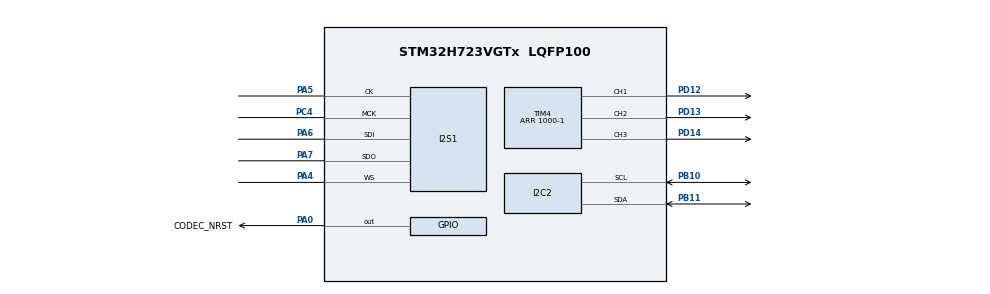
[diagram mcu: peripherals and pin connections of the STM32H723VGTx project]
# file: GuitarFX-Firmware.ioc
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CORTEX_M7.default_mode_Activation=1
Dma.Request0=SPI1_TX
Dma.Request1=SPI1_RX
Dma.SPI1_RX.1.Direction=DMA_PERIPH_TO_MEMORY
Dma.SPI1_RX.1.EventEnable=DISABLE
Dma.SPI1_RX.1.FIFOMode=DMA_FIFOMODE_DISABLE
Dma.SPI1_RX.1.Instance=DMA1_Stream1
Dma.SPI1_RX.1.MemDataAlignment=DMA_MDATAALIGN_WORD
Dma.SPI1_RX.1.MemInc=DMA_MINC_ENABLE
Dma.SPI1_RX.1.Mode=DMA_CIRCULAR
Dma.SPI1_RX.1.PeriphDataAlignment=DMA_PDATAALIGN_WORD
Dma.SPI1_RX.1.PeriphInc=DMA_PINC_DISABLE
Dma.SPI1_RX.1.Polarity=HAL_DMAMUX_REQ_GEN_RISING
Dma.SPI1_RX.1.Priority=DMA_PRIORITY_VERY_HIGH
Dma.SPI1_RX.1.RequestNumber=1
Dma.SPI1_RX.1.SignalID=NONE
Dma.SPI1_RX.1.SyncEnable=DISABLE
Dma.SPI1_RX.1.SyncPolarity=HAL_DMAMUX_SYNC_NO_EVENT
Dma.SPI1_RX.1.SyncRequestNumber=1
Dma.SPI1_RX.1.SyncSignalID=NONE
Dma.SPI1_TX.0.Direction=DMA_MEMORY_TO_PERIPH
Dma.SPI1_TX.0.EventEnable=DISABLE
Dma.SPI1_TX.0.FIFOMode=DMA_FIFOMODE_DISABLE
Dma.SPI1_TX.0.Instance=DMA1_Stream0
Dma.SPI1_TX.0.MemDataAlignment=DMA_MDATAALIGN_WORD
Dma.SPI1_TX.0.MemInc=DMA_MINC_ENABLE
Dma.SPI1_TX.0.Mode=DMA_CIRCULAR
Dma.SPI1_TX.0.PeriphDataAlignment=DMA_PDATAALIGN_WORD
Dma.SPI1_TX.0.PeriphInc=DMA_PINC_DISABLE
Dma.SPI1_TX.0.Polarity=HAL_DMAMUX_REQ_GEN_RISING
Dma.SPI1_TX.0.Priority=DMA_PRIORITY_VERY_HIGH
Dma.SPI1_TX.0.RequestNumber=1
Dma.SPI1_TX.0.SignalID=NONE
Dma.SPI1_TX.0.SyncEnable=DISABLE
Dma.SPI1_TX.0.SyncPolarity=HAL_DMAMUX_SYNC_NO_EVENT
Dma.SPI1_TX.0.SyncRequestNumber=1
Dma.SPI1_TX.0.SyncSignalID=NONE
I2C2.Timing=0x60404E72
I2S1.AudioFreq=I2S_AUDIOFREQ_32K
I2S1.Data24BitAlignment=I2S_DATA_24BIT_ALIGNMENT_LEFT
I2S1.DataFormat=I2S_DATAFORMAT_24B
I2S1.ErrorAudioFreq=1.72 %
I2S1.Instance=SPI$Index
I2S1.RealAudioFreq=32.552 KHz
Mcu.Family=STM32H7
Mcu.Name=STM32H723VGTx
Mcu.Package=LQFP100
NVIC.DMA1_Stream0_IRQn=true\:0\:0\:false\:false\:true\:false\:true\:true
NVIC.DMA1_Stream1_IRQn=true\:0\:0\:false\:false\:true\:false\:true\:true
NVIC.PriorityGroup=NVIC_PRIORITYGROUP_4
PA0.GPIO_Label=CODEC_NRST
PA0.Signal=GPIO_Output
PA13(JTMS/SWDIO).Mode=Trace_Asynchronous_SW
PA13(JTMS/SWDIO).Signal=DEBUG_JTMS-SWDIO
PA14(JTCK/SWCLK).Mode=Trace_Asynchronous_SW
PA14(JTCK/SWCLK).Signal=DEBUG_JTCK-SWCLK
PA4.Mode=Full_Duplex_Master
PA4.Signal=I2S1_WS
PA5.Mode=Full_Duplex_Master
PA5.Signal=I2S1_CK
PA6.Mode=Full_Duplex_Master
PA6.Signal=I2S1_SDI
PA7.Mode=Full_Duplex_Master
PA7.Signal=I2S1_SDO
PB10.Mode=I2C
PB10.Signal=I2C2_SCL
PB11.Mode=I2C
PB11.Signal=I2C2_SDA
PB3(JTDO/TRACESWO).Mode=Trace_Asynchronous_SW
PB3(JTDO/TRACESWO).Signal=DEBUG_JTDO-SWO
PC4.Mode=Master_Clock_Activated
PC4.Signal=I2S1_MCK
PD12.Signal=S_TIM4_CH1
PD13.Signal=S_TIM4_CH2
PD14.Signal=S_TIM4_CH3
PH0-OSC_IN.Mode=HSE-External-Oscillator
PH0-OSC_IN.Signal=RCC_OSC_IN
PH1-OSC_OUT.Mode=HSE-External-Oscillator
PH1-OSC_OUT.Signal=RCC_OSC_OUT
ProjectManager.HeapSize=0x200
ProjectManager.StackSize=0x400
ProjectManager.TargetToolchain=Makefile
RCC.ADCFreq_Value=48375000
RCC.APB1Freq_Value=137500000
RCC.APB2Freq_Value=137500000
RCC.APB3Freq_Value=137500000
RCC.APB4Freq_Value=137500000
RCC.CortexFreq_Value=550000000
RCC.D1PPRE=RCC_APB3_DIV2
RCC.D2PPRE1=RCC_APB1_DIV2
RCC.D2PPRE2=RCC_APB2_DIV2
RCC.D3PPRE=RCC_APB4_DIV2
RCC.DIVM1=3
RCC.DIVN1=68
RCC.DIVP1=1
RCC.DIVQ1=3
RCC.HCLKFreq_Value=275000000
RCC.HPRE=RCC_HCLK_DIV2
RCC.HSE_VALUE=24000000
RCC.PLL2FRACN=0
RCC.PLL3FRACN=0
RCC.PLLFRACN=6144
RCC.PLLSourceVirtual=RCC_PLLSOURCE_HSE
RCC.SYSCLKFreq_VALUE=550000000
RCC.SYSCLKSource=RCC_SYSCLKSOURCE_PLLCLK
RCC.USBFreq_Value=183333333.33333334
SH.S_TIM4_CH1.0=TIM4_CH1,PWM Generation1 CH1
SH.S_TIM4_CH2.0=TIM4_CH2,PWM Generation2 CH2
SH.S_TIM4_CH3.0=TIM4_CH3,PWM Generation3 CH3
TIM4.Channel-PWM\ Generation1\ CH1=TIM_CHANNEL_1
TIM4.Channel-PWM\ Generation2\ CH2=TIM_CHANNEL_2
TIM4.Channel-PWM\ Generation3\ CH3=TIM_CHANNEL_3
TIM4.Period=1000-1
VP_MEMORYMAP_VS_MEMORYMAP.Mode=CurAppReg
board=custom

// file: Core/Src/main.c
/* USER CODE BEGIN Header */
/**
  ******************************************************************************
  * @file           : main.c
  * @brief          : Main program body
  ******************************************************************************
  * @attention
  *
  * Copyright (c) 2026 STMicroelectronics.
  * All rights reserved.
  *
  * This software is licensed under terms that can be found in the LICENSE file
  * in the root directory of this software component.
  * If no LICENSE file comes with this software, it is provided AS-IS.
  *
  ******************************************************************************
  */
/* USER CODE END Header */
#include "main.h"
#include "dma.h"
#include "i2c.h"
#include "i2s.h"
#include "tim.h"
#include "gpio.h"

/* USER CODE BEGIN Includes */
#include "PCM3060-Codec.h"
#include "audio_stream.h"
#include "audio_process.h"
#include "gain.h"
#include "delay.h"

#include <stddef.h>
/* USER CODE END Includes */

void SystemClock_Config(void);
static void MPU_Config(void);

int main(void)
{

  /* MPU Configuration--------------------------------------------------------*/
  MPU_Config();

  /* MCU Configuration--------------------------------------------------------*/

  /* Reset of all peripherals, Initializes the Flash interface and the Systick. */
  HAL_Init();

  /* Configure the system clock */
  SystemClock_Config();

  /* Initialize all configured peripherals */
  MX_GPIO_Init();
  MX_DMA_Init();
  MX_I2S1_Init();
  MX_I2C2_Init();
  MX_TIM4_Init();
  /* USER CODE BEGIN 2 */
  PCM3060_Init();
  audio_stream_init();
  /* USER CODE END 2 */

  /* Infinite loop */
  /* USER CODE BEGIN WHILE */
  delay_effect_t delay_effect = {
    .process = delay_process,
    .reset = delay_reset,
  };
  delay_init();

  while (1)
  {
    audio_process_poll(delay_effect);
    /* USER CODE END WHILE */

  }
}

void SystemClock_Config(void)
{
  RCC_OscInitTypeDef RCC_OscInitStruct = {0};
  RCC_ClkInitTypeDef RCC_ClkInitStruct = {0};

  /** Supply configuration update enable
  */
  HAL_PWREx_ConfigSupply(PWR_LDO_SUPPLY);

  /** Configure the main internal regulator output voltage
  */
  __HAL_PWR_VOLTAGESCALING_CONFIG(PWR_REGULATOR_VOLTAGE_SCALE0);

  while(!__HAL_PWR_GET_FLAG(PWR_FLAG_VOSRDY)) {}

  /** Initializes the RCC Oscillators according to the specified parameters
  * in the RCC_OscInitTypeDef structure.
  */
  RCC_OscInitStruct.OscillatorType = RCC_OSCILLATORTYPE_HSE;
  RCC_OscInitStruct.HSEState = RCC_HSE_ON;
  RCC_OscInitStruct.PLL.PLLState = RCC_PLL_ON;
  RCC_OscInitStruct.PLL.PLLSource = RCC_PLLSOURCE_HSE;
  RCC_OscInitStruct.PLL.PLLM = 3;
  RCC_OscInitStruct.PLL.PLLN = 68;
  RCC_OscInitStruct.PLL.PLLP = 1;
  RCC_OscInitStruct.PLL.PLLQ = 3;
  RCC_OscInitStruct.PLL.PLLR = 2;
  RCC_OscInitStruct.PLL.PLLRGE = RCC_PLL1VCIRANGE_3;
  RCC_OscInitStruct.PLL.PLLVCOSEL = RCC_PLL1VCOWIDE;
  RCC_OscInitStruct.PLL.PLLFRACN = 6144;
  if (HAL_RCC_OscConfig(&RCC_OscInitStruct) != HAL_OK)
  {
    Error_Handler();
  }

  /** Initializes the CPU, AHB and APB buses clocks
  */
  RCC_ClkInitStruct.ClockType = RCC_CLOCKTYPE_HCLK|RCC_CLOCKTYPE_SYSCLK
                              |RCC_CLOCKTYPE_PCLK1|RCC_CLOCKTYPE_PCLK2
                              |RCC_CLOCKTYPE_D3PCLK1|RCC_CLOCKTYPE_D1PCLK1;
  RCC_ClkInitStruct.SYSCLKSource = RCC_SYSCLKSOURCE_PLLCLK;
  RCC_ClkInitStruct.SYSCLKDivider = RCC_SYSCLK_DIV1;
  RCC_ClkInitStruct.AHBCLKDivider = RCC_HCLK_DIV2;
  RCC_ClkInitStruct.APB3CLKDivider = RCC_APB3_DIV2;
  RCC_ClkInitStruct.APB1CLKDivider = RCC_APB1_DIV2;
  RCC_ClkInitStruct.APB2CLKDivider = RCC_APB2_DIV2;
  RCC_ClkInitStruct.APB4CLKDivider = RCC_APB4_DIV2;

  if (HAL_RCC_ClockConfig(&RCC_ClkInitStruct, FLASH_LATENCY_3) != HAL_OK)
  {
    Error_Handler();
  }
}

 /* MPU Configuration */

void MPU_Config(void)
{
  MPU_Region_InitTypeDef MPU_InitStruct = {0};

  /* Disables the MPU */
  HAL_MPU_Disable();

  /** Initializes and configures the Region and the memory to be protected
  */
  MPU_InitStruct.Enable = MPU_REGION_ENABLE;
  MPU_InitStruct.Number = MPU_REGION_NUMBER0;
  MPU_InitStruct.BaseAddress = 0x0;
  MPU_InitStruct.Size = MPU_REGION_SIZE_4GB;
  MPU_InitStruct.SubRegionDisable = 0x87;
  MPU_InitStruct.TypeExtField = MPU_TEX_LEVEL0;
  MPU_InitStruct.AccessPermission = MPU_REGION_NO_ACCESS;
  MPU_InitStruct.DisableExec = MPU_INSTRUCTION_ACCESS_DISABLE;
  MPU_InitStruct.IsShareable = MPU_ACCESS_SHAREABLE;
  MPU_InitStruct.IsCacheable = MPU_ACCESS_NOT_CACHEABLE;
  MPU_InitStruct.IsBufferable = MPU_ACCESS_NOT_BUFFERABLE;

  HAL_MPU_ConfigRegion(&MPU_InitStruct);
  /* Enables the MPU */
  HAL_MPU_Enable(MPU_PRIVILEGED_DEFAULT);

}

void Error_Handler(void)
{
  __disable_irq();
  while (1)
  {
  }
}
